# pse84_a0 register map
Vendor: Infineon Technologies; Series: PSE84_A0; File version: 1.0
CPU: CM33 r0p1, little endian, MPU, FPU, VTOR, 3 interrupt priority bits
Registers are 32-bit, read-write, reset 0x0 unless marked. A register's access mark holds for its fields unless they carry their own. Offsets are from the block's base; [hi:lo] are bit positions; lines under a group give offsets from that group; {n}, {i} and the like mark numbered series; 'fields as' and 'values as' point back to an identical list; <NAME> marks a mode.

## SRSS (part 1 of 2) — SRSS Core Registers
Base 0x42400000
{0x100+4i} CLK_DSI_SELECT[{i}] (i=0..15) — Clock DSI Select Register
  [4:0] DSI_MUX — Selects a DSI source or low frequency clock for use in a clock path. The output of this mux can be selected for clock PATH<i> using CLK_SELECT_PATH register. Using the output of this mux as HFCLK source will result in undefined behavior. It can be used to clocks to DSI or as reference inputs for the FLL/PLL, subject to the frequency limits of those circuits. This mux is not glitch free, so do not change the selection while it is an actively selected clock.
    {v}=DSI_OUT{v} (DSI{v} - dsi_out[{v}]) (v=0..15); 16=ILO (ILO - Internal Low-speed Oscillator #0); 17=WCO (WCO - Watch-Crystal Oscillator); 18=ALTLF (ALTLF - Alternate Low-Frequency Clock); 19=PILO (PILO - Precision Internal Low-speed Oscillator)
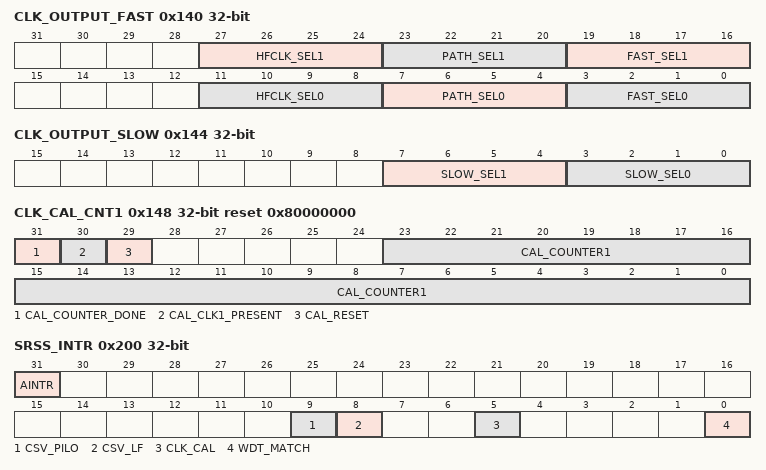
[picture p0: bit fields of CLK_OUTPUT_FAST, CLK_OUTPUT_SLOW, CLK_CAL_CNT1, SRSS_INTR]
0x140 CLK_OUTPUT_FAST — Fast Clock Output Select Register
  [27:24] HFCLK_SEL1 — Selects a HFCLK tree for use in fast clock output #1 logic
  [23:20] PATH_SEL1 — Selects a clock path to use in fast clock output #1 logic.
  [19:16] FAST_SEL1 — Select signal for fast clock output #1
    0=NC (Disabled - output is 0. For power savings, clocks are blocked before entering any muxes, including PATH_SEL1 and HFCLK_SEL1.); 1=HFSRC_0 (IHO - Internal High-speed Oscillator); 2=HFSRC_1 (EXTCLK - External Clock Pin); 3=HFSRC_2 (ECO - External-Crystal Oscillator (Product Specific)); 4=HFSRC_3 (IMO - Internal R/C Oscillator (Product Specific)); 5=HFSRC_4 (ALTHF0 - Alternate High-Frequency clock input (product-specific clock)); 6=HFSRC_5 (ALTHF1 - Alternate High-Frequency clock input (product-specific clock)); 7=HFSRC_6 (N/A); 8=TIMERCLK (Timer clock. It is grouped with the fast clocks because it may be a gated version of a fast clock, and therefore may have a short high pulse.); 9=PATH_SEL1 (Selects the clock path chosen by PATH_SEL1 field); 10=HFCLK_SEL1 (Selects the output of the HFCLK_SEL1 mux); 11=SLOW_SEL1 (Selects the output of CLK_OUTPUT_SLOW.SLOW_SEL1); 12=PWR (clk_pwr: used for PPU and related components)
  [11:8] HFCLK_SEL0 — Selects a HFCLK tree for use in fast clock output #0
  [7:4] PATH_SEL0 — Selects a clock path to use in fast clock output #0 logic.
  [3:0] FAST_SEL0 — Select signal for fast clock output #0
    0=NC (Disabled - output is 0. For power savings, clocks are blocked before entering any muxes, including PATH_SEL0 and HFCLK_SEL0.); 1=HFSRC_0 (IHO - Internal High-speed Oscillator); 2=HFSRC_1 (EXTCLK - External Clock Pin); 3=HFSRC_2 (ECO - External-Crystal Oscillator (Product Specific)); 4=HFSRC_3 (IMO - Internal R/C Oscillator (Product Specific)); 5=HFSRC_4 (ALTHF0 - Alternate High-Frequency clock input (product-specific clock)); 6=HFSRC_5 (ALTHF1 - Alternate High-Frequency clock input (product-specific clock)); 7=HFSRC_6 (N/A); 8=TIMERCLK (Timer clock. It is grouped with the fast clocks because it may be a gated version of a fast clock, and therefore may have a short high pulse.); 9=PATH_SEL0 (Selects the clock path chosen by PATH_SEL0 field); 10=HFCLK_SEL0 (Selects the output of the HFCLK_SEL0 mux); 11=SLOW_SEL0 (Selects the output of CLK_OUTPUT_SLOW.SLOW_SEL0); 12=PWR (clk_pwr: used for PPU and related components)
0x144 CLK_OUTPUT_SLOW — Slow Clock Output Select Register
  [7:4] SLOW_SEL1 — Select signal for slow clock output #1
    0=NC (Disabled - output is 0. For power savings, clocks are blocked before entering any muxes.); 1=ILO (Internal Low Speed Oscillator (ILO)); 2=WCO (Watch-Crystal Oscillator (WCO)); 3=CLK_RTC (Root of the RTC clock tree); 4=ALTLF (Alternate low-frequency clock input to SRSS (ALTLF)); 5=LFCLK (Root of the low-speed clock tree (LFCLK)); 6=IMO (Internal Main Oscillator (IMO). This is grouped with the slow clocks so it can be observed during DEEPSLEEP entry/exit.); 7=SLPCTRL (Sleep Controller clock (SLPCTRL). This is grouped with the slow clocks so it can be observed during DEEPSLEEP entry/exit.); 8=PILO (Precision Internal Low Speed Oscillator (PILO)); 9=ECO_PRESCALER (ECO Prescaler (ECO_PRESCALER)); 10=MF (Medium Frequency clock tree (MF)); 11=RSVD1 (N/A); 12=RSVD2 (N/A); 13=RSVD3 (N/A)
  [3:0] SLOW_SEL0 — Select signal for slow clock output #0
    values as SLOW_SEL1
0x148 CLK_CAL_CNT1 reset 0x80000000 — Clock Calibration Counter 1
  [31] CAL_COUNTER_DONE ro — Status bit indicating that the internal counter #1 is finished counting and CLK_CAL_CNT2.COUNTER stopped counting up
  [30] CAL_CLK1_PRESENT ro — Status bit indicating that a posedge was detected by counter #1 (does not apply when CLK_CAL_TEST.CAL_WINDOW_SEL = 1). If this bit never asserts, there is no clock on counter #1 and CAL_COUNTER_DONE will stay low indefinitely. This can be recovered with CAL_RESET.
  [29] CAL_RESET — Reset clock calibration logic for window mode. This can be used to recover from unexpected conditions, such as no clock present on counter #1. When entering window mode, set this bit, then set CLK_CAL_TEST.CAL_WINDOW_SEL=1, then clear this bit. It takes 3 clock cycles for this reset to propagate. A new calibration cannot start during this time.
  [23:0] CAL_COUNTER1 — Down-counter clocked on fast clock output #0 (see CLK_OUTPUT_FAST). This register always reads as zero. Counting starts internally when this register is written with a nonzero value. CAL_COUNTER_DONE goes immediately low to indicate that the counter has started and will be asserted when the counters are done. Do not write this field unless CAL_COUNTER_DONE==1. Both clocks must be running or the measurement will not complete, and this case can be recovered using CAL_RESET.
0x14C CLK_CAL_CNT2 ro — Clock Calibration Counter 2
  [23:0] CAL_COUNTER2 — Up-counter clocked on fast clock output #1 (see CLK_OUTPUT_FAST). When CLK_CAL_CNT1.CAL_COUNTER_DONE==1, the counter is stopped and can be read by SW. Do not read this value unless CAL_COUNTER_DONE==1. The expected final value is related to the ratio of clock frequencies used for the two counters and the value loaded into counter 1: CLK_CAL_CNT2.COUNTER=(F_cnt2/F_cnt1)*(CLK_CAL_CNT1.COUNTER)
0x200 SRSS_INTR — SRSS Interrupt Register
  [31] AINTR ro — See additional interrupts in SRSS_AINTR.
  [9] CSV_PILO — CSV_PILO Interrupt Request. This bit is set when PILO clock is below or above the expected limit
  [8] CSV_LF — CSV_LF Interrupt Request. This bit is set when LFCLK is below or above the expected limit
  [5] CLK_CAL — Clock calibration counter is done. This field is reset during DEEPSLEEP mode.
  [0] WDT_MATCH — WDT Interrupt Request. This bit is set each time WDT_COUNTR==WDT_MATCH. W1C also feeds the watch dog. Missing 2 interrupts in a row will generate a reset. Due to internal synchronization, it takes 2 SYSCLK cycles to update after a W1C.
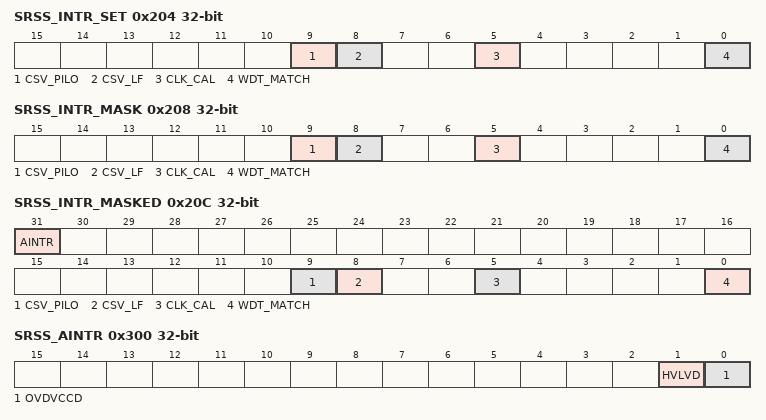
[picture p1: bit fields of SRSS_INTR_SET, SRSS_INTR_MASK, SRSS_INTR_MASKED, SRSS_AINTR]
0x204 SRSS_INTR_SET — SRSS Interrupt Set Register
  [9] CSV_PILO — Set interrupt for CSV_PILO
  [8] CSV_LF — Set interrupt for CSV_LF
  [5] CLK_CAL — Set interrupt for clock calibration counter done. This field is reset during DEEPSLEEP mode.
  [0] WDT_MATCH — Set interrupt for low voltage detector WDT_MATCH
0x208 SRSS_INTR_MASK — SRSS Interrupt Mask Register
  [9] CSV_PILO — Mask for interrupt for CSV_PILO
  [8] CSV_LF — Mask for interrupt for CSV_LF
  [5] CLK_CAL — Mask for clock calibration done
  [0] WDT_MATCH — Mask for watchdog timer. Clearing this bit will not forward the interrupt to the CPU. It will not, however, disable the WDT reset generation on 2 missed interrupts. When WDT resets the chip, it also internally pends an interrupt that survives the reset. To prevent unintended ISR execution, clear SRSS_INTR.WDT_MATCH before setting this bit.
0x20C SRSS_INTR_MASKED ro — SRSS Interrupt Masked Register
  [31] AINTR — See additional MASKED bits in SRSS_AINTR_MASKED.ADDITIONAL
  [9] CSV_PILO — Logical and of corresponding request and mask bits.
  [8] CSV_LF — Logical and of corresponding request and mask bits.
  [5] CLK_CAL — Logical and of corresponding request and mask bits.
  [0] WDT_MATCH — Logical and of corresponding request and mask bits.
0x300 SRSS_AINTR — SRSS Additional Interrupt Register
  [1] HVLVD — Interrupt for low voltage detector HVLVD
  [0] OVDVCCD — Interrupt for low voltage detector OVDVCCD. The OVD status should be cleared in PWR_SSV_STATUS before clearing this interrupt.
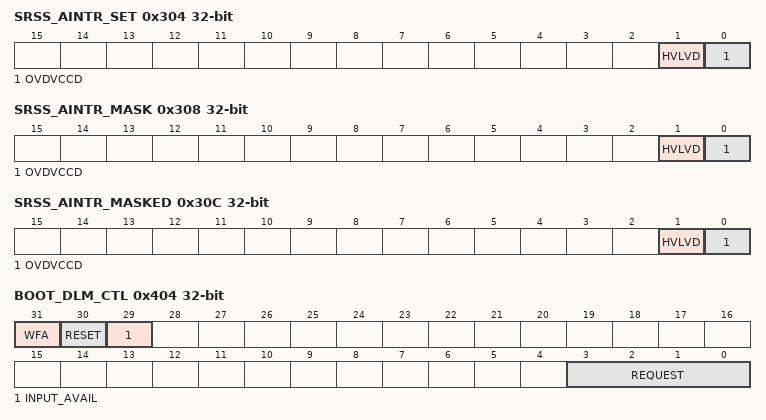
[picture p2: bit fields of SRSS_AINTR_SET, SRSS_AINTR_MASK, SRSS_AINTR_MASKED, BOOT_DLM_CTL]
0x304 SRSS_AINTR_SET — SRSS Additional Interrupt Set Register
  [1] HVLVD — Set interrupt for low voltage detector HVLVD. Note that the PWR_LVD_CTL.HVLVD_ACTION must be set to Interrupt for this SET functionality to work.
  [0] OVDVCCD — Set interrupt for low voltage detector OVDVCCD. Note that the PWR_OVD_CTL.OVDVCCD_ACTION must be set to Interrupt for this SET functionality to work.
0x308 SRSS_AINTR_MASK — SRSS Additional Interrupt Mask Register
  [1] HVLVD — Mask for low voltage detector HVLVD
  [0] OVDVCCD — Mask for low voltage detector OVDVCCD
0x30C SRSS_AINTR_MASKED ro — SRSS Additional Interrupt Masked Register
  [1] HVLVD — Logical and of corresponding request and mask bits.
  [0] OVDVCCD — Logical and of corresponding request and mask bits.
0x340 PWR_LVD_STATUS ro — High Voltage / Low Voltage Detector (HVLVD) Status Register
  [0] HVLVD_OK — HVLVD output. 0: below voltage threshold 1: above voltage threshold
0x404 BOOT_DLM_CTL — Debug Control Register
  [31] WFA — Wait for Action. Set by BootROM when it waits for application or debug certificate to be loaded into the RAM. The bit must be cleared to continue BootROM operation. It is used by the Sys-AP.
  [30] RESET — Request the device reset after RAM application complete input parameters processing. This bit is analyzed with APP_INPUT_AVAIL so to take effect write both. 0 - No action, the device waits for input parameters. 1 - Reset the device after input parameters processing complete.
  [29] INPUT_AVAIL — Notify RAM application that input parameters are valid for processing: 0 - the input parameters are not available. 1 - the input parameters are available (ready) for processing.
  [3:0] REQUEST
0x408 BOOT_DLM_CTL2 — Debug Control Register 2
  [31:0] APP_CTL — Address of application descriptor or debug certificate depends on DEBUG_TST_CTL.REQUEST. The application descriptor provides info about RAM application and its parameters layout in the staging area to BootROM and RAM application itself
0x40C BOOT_DLM_STATUS — Debug Status Register
  [31:0] DEBUG_STATUS — RAM application execution status or debug certificate validation status depends on DEBUG_TST_CTL.REQUEST. This status can be read by the debugger using Sys-AP or user application when RAM application completes with system reset. This field survives some resets, including a system reset
0x410 RES_SOFT_CTL — Soft Reset Trigger Register
  [0] TRIGGER_SOFT — Triggers a soft reset. The reset clears this bit.
0x418 BOOT_STATUS — Boot Execution Status Register
  [31:0] DEBUG_STATUS — Boot execution status. This status register can be used for communication between ROM_BOOT and User Application. This status can be read by the debugger using Sys-AP or User Application. This field survives some resets, including a system reset.
0x430 BOOT_ENTRY — Warm Boot Entry Address
  [31:0] WARM_BOOT_ENTRY — Warm boot entry point. This status register can be used for communication between 2 software application before/after DS-RAM or soft reset. This field survives low voltage resets, including a system reset.
{0x800+4i} PWR_HIB_DATA[{i}] (i=0..31) — Hibernate Data Register
  [31:0] HIB_DATA — Additional data that is retained through a HIBERNATE/WAKEUP sequence that can be used by firmware for any application-specific purpose. Note that waking up from HIBERNATE using XRES will reset this register.
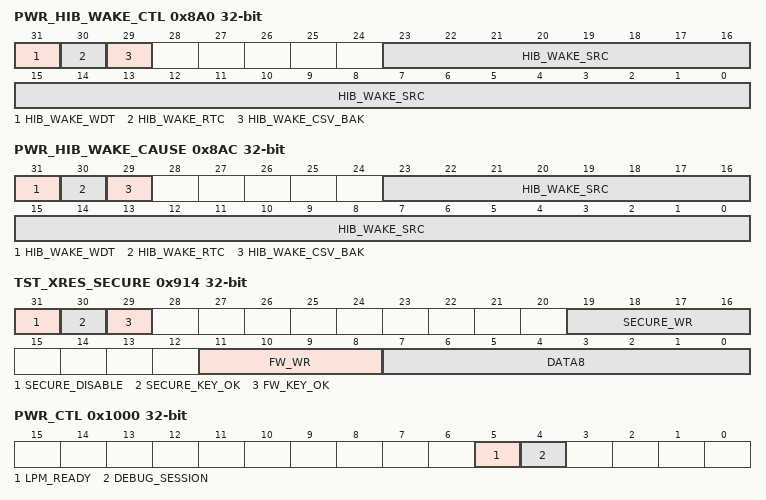
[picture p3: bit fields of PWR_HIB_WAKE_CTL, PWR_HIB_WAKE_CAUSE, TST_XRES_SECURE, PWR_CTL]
0x8A0 PWR_HIB_WAKE_CTL — Hibernate Wakeup Mask Register
  [31] HIB_WAKE_WDT — When set, HIBERNATE will wakeup for a pending WDT interrupt.
  [30] HIB_WAKE_RTC — When set, HIBERNATE will wakeup for a pending RTC interrupt.
  [29] HIB_WAKE_CSV_BAK — When set, HIBERNATE will wakeup for CSV_RTC detection.
  [23:0] HIB_WAKE_SRC — When set, HIBERNATE will wakeup for the assigned source The number and assignment of HIBERNATE wakeup sources are product-specific.
0x8A4 PWR_HIB_WAKE_CTL2 — Hibernate Wakeup Polarity Register
  [23:0] HIB_WAKE_SRC — Each bit selects the polarity for the corresponding HIBERNATE wakeup source. The number and assignment of wakeup sources are product-specific. 0: Wakes when unmasked input is 0. 1: Wakes when unmasked input is 1.
0x8AC PWR_HIB_WAKE_CAUSE — Hibernate Wakeup Cause Register
  [31] HIB_WAKE_WDT — Indicates WDT wakeup cause. The WDT interrupt must be cleared before this bit can be cleared.
  [30] HIB_WAKE_RTC — Indicates RTC wakeup cause. The RTC interrupt must be cleared before this bit can be cleared.
  [29] HIB_WAKE_CSV_BAK — Indicates CSV_RTC wakeup cause. The related fault must be handled before this bit can be cleared.
  [23:0] HIB_WAKE_SRC — Each bit indicates a HIBERNATE wakeup cause. The number and assigment of wakeup sources are product-specific. For each bit, writing a 1 clears the cause flag.
0x914 TST_XRES_SECURE — SECURE TEST and FIRMWARE TEST Key control register
  [31] SECURE_DISABLE — Disables the SECURE TEST key entry capability until next reset. Must not be set in the same write when any of the above *_WR bits are set or toggling.
  [30] SECURE_KEY_OK ro — Indicates that the 32-bit SECURE TEST key is observing the correct key. Secure key is not reset, but it will establish low after a deep power cycle that causes it to lose its written state.
  [29] FW_KEY_OK ro — Indicates that the 32-bit FIRMWARE TEST key is observing the correct key. Firmware key is reset by (A)XRES and STRUCT_XRES.
  [19:16] SECURE_WR — Latch enables for each of the 4 bytes in the 32-bit SECURE TEST key. Must be toggled high and then low while keeping DATA8 to the correct value.
  [11:8] FW_WR — Latch enables for each of the 4 bytes in the 32-bit FIRMWARE TEST key. Must be toggled high and then low while keeping DATA8 to the correct value.
  [7:0] DATA8 — Data byte to be set into either SECURE TEST or FIRMWARE TEST key. Must not be changed in the same write that is toggling any of the *_WR bits below,
0x1000 PWR_CTL ro — Power Mode Control
  [5] LPM_READY — Indicates whether certain low power functions are ready. The low current circuits take longer to startup after XRES, HIBERNATE wakeup, or supply supervision reset wakeup than the normal mode circuits. HIBERNATE mode may be entered regardless of this bit. 0: If a low power circuit operation is requested, it will stay in its normal operating mode until it is ready. If DEEPSLEEP is requested by all processors WFI/WFE, the device will instead enter SLEEP. When low power circuits are ready, device will automatically enter the originally requested mode. 1: Normal operation. DEEPSLEEP and low power circuits operate as requested in other registers.
  [4] DEBUG_SESSION — Indicates whether a debug session is active (CDBGPWRUPREQ signal is 1)
    0=NO_SESSION (No debug session active); 1=SESSION_ACTIVE (Debug session is active. Power modes behave differently to keep the debug session active, and current consumption may be higher than datasheet specification.)
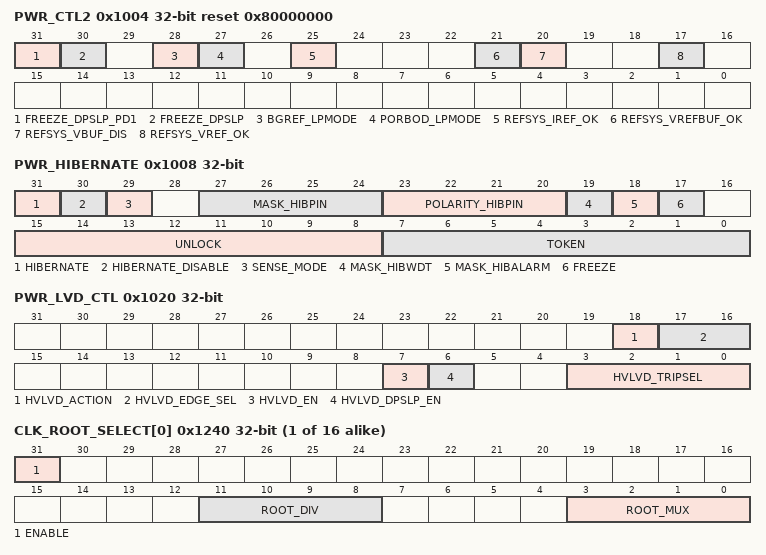
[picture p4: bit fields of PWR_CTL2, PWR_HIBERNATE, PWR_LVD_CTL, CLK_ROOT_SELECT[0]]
0x1004 PWR_CTL2 reset 0x80000000 — Power Mode Control 2
  [31] FREEZE_DPSLP_PD1 — Controls whether mode and state of GPIOs and SIOs in Power Domain 1 are frozen. This is intended to be used as part of the DEEPSLEEP-RAM and DEEPSLEEP-OFF entry and exit sequences. It is set by HW when PD1 enters DEEPSLEEP-RAM and DEEPSLEEP-OFF modes. Writing a 1 clears freeze and GPIOs and SIOs resume normal operation.
  [30] FREEZE_DPSLP — Controls whether mode and state of GPIOs and SIOs in Power Domain 0 are frozen. This is intended to be used as part of the DEEPSLEEP-RAM and DEEPSLEEP-OFF entry and exit sequences. It is set by HW when PD0 enters DEEPSLEEP-RAM and DEEPSLEEP-OFF modes. Writing a 1 clears freeze and GPIOs and SIOs resume normal operation.
  [28] BGREF_LPMODE — Control the circuit-level power mode of the Bandgap Reference circuits for DEEPSLEEP. This selects a second set of bandgap voltage and current generation circuits that are optimized for low current consumption. This register is only reset by XRES, HIBERNATE wakeup, or supply supervision reset. The setting is ignored during ACTIVE mode. 0: Bandgap Reference uses the normal settings. 1: Bandgap Reference uses the low power sample and hold circuits.
  [27] PORBOD_LPMODE — Control the power mode of the POR/BOD circuits in DEEPSLEEP modes. The value in this register is ignored and normal mode is used until LPM_READY==1. This register is only reset by XRES, HIBERNATE wakeup, or supply supervision reset. 0: POR/BOD circuits operate in normal mode during DEEPSLEEP. 1: POR/BOD circuits operate in low power mode during DEEPSLEEP. Response time is reduced to save current.
  [25] REFSYS_IREF_OK ro — Indicates that the current reference is ready. Due to synchronization delays, it may take two IHO clock cycles for hardware to clear this bit after asserting REFI_DIS=1.
  [21] REFSYS_VREFBUF_OK ro — Indicates that the voltage reference buffer is ready. Due to synchronization delays, it may take two IHO clock cycles for hardware to clear this bit after asserting REFVBUF_DIS=1.
  [20] REFSYS_VBUF_DIS — Disable the voltage reference buffer. Firmware should only disable the buffer when there is no connected circuit that is using it. SRSS circuits that require it are the DPLL and ECO. A particular product may have circuits outside the SRSS that use the buffer. This register is only reset by XRES, HIBERNATE wakeup, or supply supervision reset.
  [17] REFSYS_VREF_OK ro — Indicates that the normal mode of the voltage reference is ready.
0x1008 PWR_HIBERNATE — HIBERNATE Mode Register
  [31] HIBERNATE — Firmware sets this bit to enter HIBERNATE mode. The system will enter HIBERNATE mode immediately after writing to this bit and will wakeup only in response to XRES or WAKEUP. Both UNLOCK and FREEZE must have been set correctly in a previous write operations. Otherwise, it will not enter HIBERNATE. External supplies must have been stable for 250us before entering HIBERNATE mode.
  [30] HIBERNATE_DISABLE — Hibernate disable bit. 0: Normal operation, HIBERNATE works as described 1: Further writes to this register are ignored Note: This bit is a write-once bit until the next reset. Avoid changing any other bits in this register while disabling HIBERNATE mode. Also, it is recommended to clear the UNLOCK code, if it was previously written..
  [29] SENSE_MODE — Power mode when wakeups are sensitive. The default of this field is 0 for software compatibility with other products. It is recommended to set this field to 1 for new/updated software. 0: Wakeups are sensitive only during HIBERNATE mode. A wakeup pulse that comes just before HIBERNATE entry may be missed. Backward compatible. 1: Wakeups are sensitive in HIBERNATE and higher modes. Before entering HIBERNATE, software must clear all unmasked, pending wakeups in PWR_HIB_WAKE_CAUSE register. An unmasked, pending wakeup causes HIBERNATE wakeup, even if it was pending from before HIBERNATE entry. This prevents missed wakeups.
  [27:24] MASK_HIBPIN
  [23:20] POLARITY_HIBPIN
  [19] MASK_HIBWDT
  [18] MASK_HIBALARM
  [17] FREEZE — Controls whether mode and state of GPIOs and SIOs in the system are frozen. This is intended to be used as part of the HIBERNATE entry and exit sequences. When entering HIBERNATE mode, the first write instructs DEEPSLEEP peripherals that they cannot ignore the upcoming freeze command. This occurs even in the illegal condition where UNLOCK is not set. If UNLOCK and HIBERNATE are properly set, the IOs actually freeze on the second write. Supply supervision is disabled during HIBERNATE mode. HIBERNATE peripherals ignore resets (excluding XRES) while FREEZE==1.
  [15:8] UNLOCK — This byte must be set to 0x3A for FREEZE or HIBERNATE fields to operate. Any other value in this register will cause FREEZE/HIBERNATE to have no effect, except as noted in the FREEZE description.
  [7:0] TOKEN — Contains a 8-bit token that is retained through a HIBERNATE/WAKEUP sequence that can be used by firmware to differentiate WAKEUP from a general RESET event. Note that waking up from HIBERNATE using XRES,or a WDT reset will reset this register.
0x1020 PWR_LVD_CTL — High Voltage / Low Voltage Detector (HVLVD) Configuration Register
  [18] HVLVD_ACTION — Action taken when the threshold is crossed in the programmed directions(s)
    0=INTERRUPT (Generate an interrupt); 1=FAULT (Generate a fault)
  [17:16] HVLVD_EDGE_SEL — Sets which edge(s) will trigger an action when the threshold is crossed.
    0=DISABLE (Disabled); 1=RISING (Rising edge); 2=FALLING (Falling edge); 3=BOTH (Both rising and falling edges)
  [7] HVLVD_EN — Enable HVLVD voltage monitor. Do not change other HVLVD settings when enabled.
  [6] HVLVD_DPSLP_EN — 1 = Enable HVLVD voltage monitor during Deepsleep if HVLVD_EN=1, but the response will be slowed to save power. 0 = HVLVD does not function during DEEPSLEEP, but it automatically returns to its configured setting after DEEPSLEEP wakeup.
  [3:0] HVLVD_TRIPSEL — Threshold selection for HVLVD. Disable the detector (HVLVD_EN=0) before changing the threshold. 0: rise=2.78V (nom), fall=2.75V (nom) 1: rise=2.88V (nom), fall=2.85V (nom) 2: rise=2.98V (nom), fall=2.95V (nom) 3: rise=3.08V (nom), fall=3.05V (nom) 4: rise=3.18V (nom), fall=3.15V (nom)
{0x1200+4i} CLK_PATH_SELECT[{i}] (i=0..15) — Clock Path Select Register
  [2:0] PATH_MUX — Selects a source for clock PATH<i>. Note that not all products support all clock sources. Selecting a clock source that is not supported will result in undefined behavior. It takes four cycles of the originally selected clock to switch away from it. Do not disable the original clock during this time.
    0=HFSRC_0 (IHO - Internal High-speed Oscillator); 1=HFSRC_1 (EXTCLK - External Clock Pin); 2=HFSRC_2 (ECO - External-Crystal Oscillator (Product Specific)); 3=HFSRC_3 (IMO - Internal R/C Oscillator (Product Specific)); 4=HFSRC_4 (ALTHF0 - Alternate High-Frequency clock input (product-specific clock)); 5=HFSRC_5 (ALTHF1 - Alternate High-Frequency clock input (product-specific clock)); 6=HFSRC_6 (N/A); 7=HFSRC_7 (DSI_MUX - Output of DSI mux for this path. Using a DSI source directly as root of HFCLK will result in undefined behavior.)
{0x1240+4i} CLK_ROOT_SELECT[{i}] (i=0..15) — Clock Root Select Register
  [31] ENABLE — Enable for this clock root. All clock roots default to disabled (ENABLE==0) except HFCLK0, which cannot be disabled.
  [11:8] ROOT_DIV — Selects predivider value for this clock root and DSI input. This divider is after DIRECT_MUX. For products with DSI, the output of this mux is routed to DSI for use as a signal. For products with clock supervision, the output of this mux is the monitored clock for CSV_HF<k>.
    0=NO_DIV (Transparent mode, feed through selected clock source w/o dividing.); {v}=DIV_BY_{v+1} (Divide selected clock source by {v+1}) (v=1..15)
  [3:0] ROOT_MUX — Selects a clock path for HFCLK<k> and SRSS DSI input <k>. The output of this mux goes to the direct mux (see CLK_DIRECT_SELECT). Use CLK_SELECT_PATH[i] to configure the desired path. The number of clock paths is product-specific, and selecting an unimplemented path is not supported. Some paths may have PLL available (product-specific), and the control and bypass mux selections of these are in other registers. Configure a PLL using the related CLK_PLL_CONFIG[k] register. Note that not all products support all clock sources. Selecting a clock source that is not supported will result in undefined behavior. It takes four cycles of the originally selected clock to switch away from it. Do not disable the original clock during this time. When switching to a different clock source, ensure that the ROOT_DIV is set to an appropriate value BEFORE changing the ROOT_MUX to avoid a temporary over/under-shoot in clock frequency that will occur if both fields are changed at the same time.
    {v}=PATH{v} (Select PATH{v}) (v=0..15)
{0x1280+4i} CLK_DIRECT_SELECT[{i}] (i=0..15) — Clock Root Direct Select Register
  [8] DIRECT_MUX — Direct selection mux that allows IHO to bypass most of the clock mux structure. For products with multiple regulators, this mux can be used to reduce current without requiring significant reconfiguration of the clocking network. The default value of HFCLK<0>==ROOT_MUX, and the default value for other clock trees is product-specific.
    0=IHO (Select IHO); 1=ROOT_MUX (Select ROOT_MUX selection)
0x1300 CLK_SELECT — Clock selection register
  [2:0] LFCLK_SEL — Select source for LFCLK. Note that not all products support all clock sources. Selecting a clock source that is not supported will result in undefined behavior. Writes to this field are ignored unless the WDT is unlocked using WDT_LOCK register. It takes four cycles of the originally selected clock to switch away from it. Do not disable the original clock during this time.
    0=PILO (PILO - Precision ILO, if present.); 1=WCO (WCO - Watch-Crystal Oscillator. Requires properly configured (including external watch crystal, if used), if present); 2=ALTLF (ALTLF - Alternate Low-Frequency Clock. Capability is product-specific); 3=ECO_PRESCALER (ECO_PRESCALER - External-Crystal Oscillator after prescaling, if present. Does not work in DEEPSLEEP or HIBERNATE modes. Intended for applications that operate in ACTIVE/SLEEP modes only. This option is only valid when ECO is present in the product. User must ensure that the CLK_ECO_PRESCALE is configured to generate a 32KHz clock when using this option.); 4=ILO (ILO - Internal Low-speed Oscillator, if present)
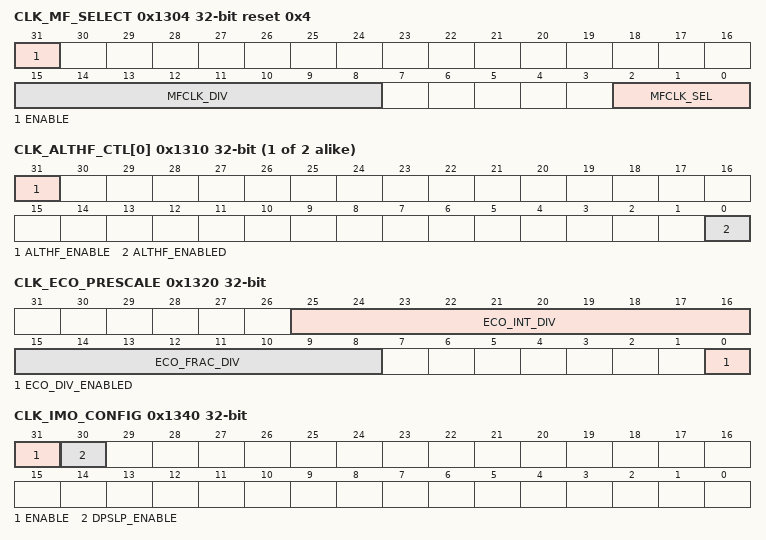
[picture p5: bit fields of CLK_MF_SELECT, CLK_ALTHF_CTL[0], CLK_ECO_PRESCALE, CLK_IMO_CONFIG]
0x1304 CLK_MF_SELECT reset 0x4 — Medium Frequency Clock Select Register
  [31] ENABLE — Enable for MFCLK (clk_mf). When disabling clk_mf, do not disable the source until after 5 clk_mf periods. clk_mf continues to operate in DEEPSLEEP for compatible sources. Firmware must disable clk_mf before entering DEEPSLEEP if the source is not compatible with DEEPSLEEP mode.
  [15:8] MFCLK_DIV — Divide selected clock source by (1+MFCLK_DIV). The output of this divider is MFCLK (clk_mf). Allows for integer divisions in the range [1, 256]. Do not change this setting while ENABLE==1.
  [2:0] MFCLK_SEL — Select source for MFCLK (clk_mf). Note that not all products support all clock sources. Selecting a clock source that is not supported results in undefined behavior.
    0=IMO (Internal Main Oscillator (IMO). DEEPSLEEP compatibility is product-specific. See CLK_IMO_CONFIG for capability of this product.); 1=ILO (ILO - Internal Low-speed Oscillator.); 2=WCO (WCO - Watch-Crystal Oscillator, if present.); 3=ALTLF (ALTLF - Alternate Low-Frequency Clock. Capability is product-specific); 4=PILO (PILO - Precision ILO, if present.); 5=ECO_PRESCALER (ECO_PRESCALER - External-Crystal Oscillator, if present, after prescaling in CLK_ECO_PRESCALE. Intended for applications that operate in ACTIVE/SLEEP modes only. Does not work in DEEPSLEEP mode.); 6=IHO (IHO clock. MFCLK_DIV should be >0 to achieve MF frequency. DEEPSLEEP compatibility is product-specific. See CLK_IHO_CONFIG for capability of this product.); 7=RSVD2 (N/A)
{0x1310+4i} CLK_ALTHF_CTL[{i}] (i=0..1) — Alternate High Frequency Clock Control Register
  [31] ALTHF_ENABLE — Enable for ALTHF clock when used by SRSS. There may be independent control of ALTHF by another subsystem, and this bit prevents ALTHF from being disabled when SRSS needs it. SRSS automatically removes its enable request during DEEPSLEEP and lower modes.
  [0] ALTHF_ENABLED ro — Indicates that ALTHF is actually enabled. The delay between a transition on ALTHF_ENABLE and ALTHF_ENABLED is product specific.
0x1320 CLK_ECO_PRESCALE — ECO Prescaler Configuration Register
  [25:16] ECO_INT_DIV — 10-bit integer value allows for ECO frequencies up to 33.55MHz. Subtract one from the desired divide value when writing this field. For example, to divide by 1, write ECO_INT_DIV=0. Do not change this setting when ECO Prescaler is enabled.
  [15:8] ECO_FRAC_DIV — 8-bit fractional value, sufficient to get prescaler output within the +/-65ppm calibration range. Do not change this setting when ECO Prescaler is enabled.
  [0] ECO_DIV_ENABLED ro — ECO prescaler enabled. HW sets this field to '1' as a result of an CLK_ECO_CONFIG.ECO_DIV_ENABLE command. HW sets this field to '0' as a result on a CLK_ECO_CONFIG.ECO_DIV_DISABLE command. ECO prescaler is incompatible with DEEPSLEEP modes, and firmware must disable it before entering DEEPSLEEP.
0x1340 CLK_IMO_CONFIG — IMO Configuration
  [31] ENABLE — Master enable for IMO oscillator. Hardware will automatically disable the IMO during HIBERNATE and XRES. It will automatically disable during DEEPSLEEP if DPSLP_ENABLE==0.
  [30] DPSLP_ENABLE — Enable for IMO during DEEPSLEEP. This bit configures IMO behavior during DEEPSLEEP: 0: IMO is automatically disabled during DEEPSLEEP and enables upon wakeup; 1: IMO is kept enabled throughout DEEPSLEEP
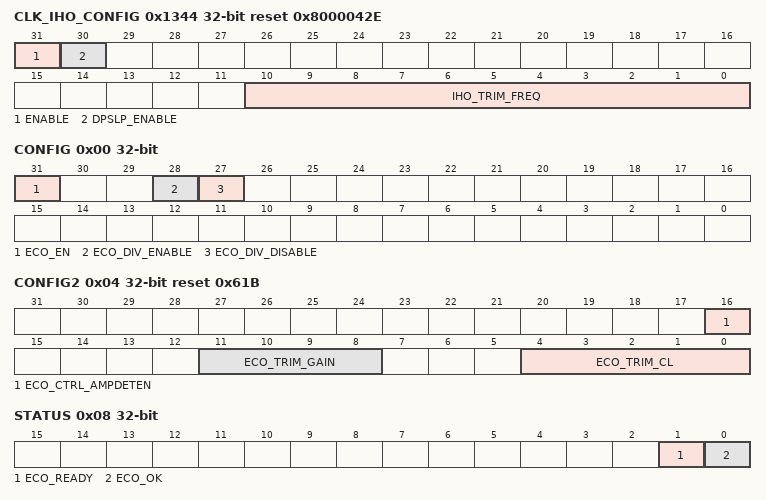
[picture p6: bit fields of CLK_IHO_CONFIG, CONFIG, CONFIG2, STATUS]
0x1344 CLK_IHO_CONFIG reset 0x8000042E — IHO Configuration Register
  [31] ENABLE — Master enable for IHO oscillator. This bit must be high at all times for all functions to work properly. Hardware will automatically disable the IHO during HIBERNATE and XRES. It will automatically disable during DEEPSLEEP if DPSLP_ENABLE==0.
  [30] DPSLP_ENABLE — Enable for IHO during DEEPSLEEP. This bit configures IHO behavior during DEEPSLEEP: 0: IHO is automatically disabled during DEEPSLEEP and enables upon wakeup; 1: IHO is kept enabled throughout DEEPSLEEP
  [10:0] IHO_TRIM_FREQ — IHO frequency trim
0x1360 CLK_ECO group — ECO Configuration
  0x00 CONFIG — ECO Configuration Register
    [31] ECO_EN — Master enable for ECO oscillator. Configure the settings in CLK_ECO_CONFIG2 to work with the selected crystal, before enabling ECO.
    [28] ECO_DIV_ENABLE — ECO prescaler enable command (mutually exclusive with ECO_DIV_DISABLE). ECO Prescaler only works in ACTIVE and SLEEP modes. SW sets this field to '1' to enable the divider and HW sets this field to '0' to indicate that divider enabling has completed. When the divider is enabled, its integer and fractional counters are initialized to '0'. If a divider is to be re-enabled using different integer and fractional divider values, the SW should follow these steps: 0: Disable the divider using the ECO_DIV_DISABLE field. 1: Configure CLK_ECO_PRESCALE registers. 2: Enable the divider using the ECO_DIV_ENABLE field. HW sets the ECO_DIV_ENABLE field to '0' when the enabling is performed and HW set CLK_ECO_PRESCALER.ENABLED to '1' when the enabling is performed.
    [27] ECO_DIV_DISABLE — ECO prescaler disable command (mutually exclusive with ECO_DIV_ENABLE). SW sets this field to '1' and HW sets this field to '0'. HW sets ECO_DIV_DISABLE field to '0' immediately and HW sets CLK_ECO_PRESCALE.ECO_DIV_EN field to '0' immediately.
  0x04 CONFIG2 reset 0x61B — ECO Configuration Register 2
    [16] ECO_CTRL_AMPDETEN — Amplifer detect enable
    [11:8] ECO_TRIM_GAIN — Gain trim
    [4:0] ECO_TRIM_CL — Crystal load cap configuration trim
  0x08 STATUS ro — ECO Status Register
    [1] ECO_READY — Indicates the ECO internal oscillator circuit power has had enough time to fully stabilize and the CLK_EN can be set. The ECO_OK bit should be used to determine that the ECO is ready for use.
    [0] ECO_OK — Indicates the ECO internal oscillator circuit has sufficient amplitude. It may not meet the PPM accuracy or duty cycle spec.
0x1370 CLK_PILO_CONFIG reset 0x80000000 — Precision ILO Configuration Register
  [31] PILO_EN — Enable PILO. If the PILO is the selected source for WDT, writes to this field are ignored unless the WDT is unlocked using WDT_LOCK register. To save power FW must disable PILO upon entry to Hibernate if it is not used as a Hibernate clock source. PILO will continue to run in XRES if enabled.
0x1374 CLK_PILO_STATUS ro — Precision ILO Status Register
  [0] PILO_OK — Indicates the PILO is running.
0x1380 CLK_ILO_CONFIG reset 0x80000000 — ILO Configuration
  [31] ENABLE — Enable ILO. If the ILO is the selected source for WDT, writes to this field are ignored unless the WDT is unlocked using WDT_LOCK register. To save power, FW must disable ILO upon entry to Hibernate if it is not used as a Hibernate clock source. ILO will continue to run in XRES if enabled.
0x1384 CLK_TRIM_ILO_CTL reset 0x2C — ILO Trim Register
  [5:0] ILO_FTRIM — IL0 frequency trims. LSB step size is 1.5 percent (typical) of the frequency. If the ILO is the selected source for WDT, writes to this field are ignored unless the WDT is unlocked using WDT_LOCK register.
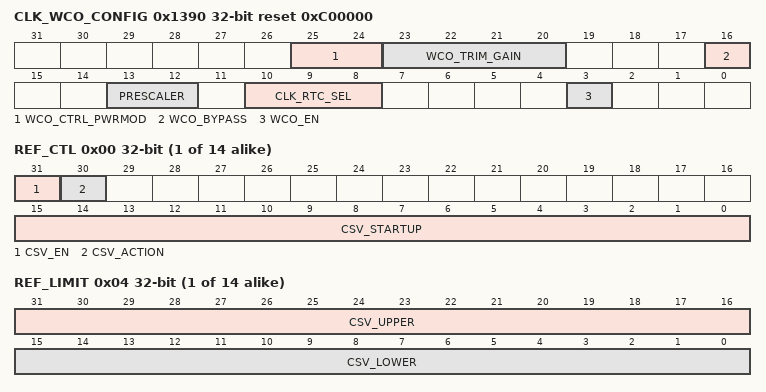
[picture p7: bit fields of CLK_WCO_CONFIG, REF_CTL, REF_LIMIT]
0x1390 CLK_WCO_CONFIG reset 0xC00000 — WCO Configuration Register
  [25:24] WCO_CTRL_PWRMOD
  [23:20] WCO_TRIM_GAIN — main amplifier gain control. Please use S22SRSSA_WCO_CALCULATOR to obtain appropriate value for the attached crystal. Writes to this field are ignored unless the WDT is unlocked using WDT_LOCK register
  [16] WCO_BYPASS — Configures the WCO for different board-level connections to the WCO pins. For example, this can be used to connect an external watch crystal oscillator instead of a watch crystal. In all cases, the two related GPIO pins (WCO input and output pins) must be configured as analog connections using GPIO registers, and they must be hooked at the board level as described below. Configure this field before enabling the WCO, and do not change this setting when WCO_EN=1. Also if the BAK (RTC) is the selected source for WDT, Writes to this field are ignored unless the WDT is unlocked using WDT_LOCK register. 0: Watch crystal. Connect a 32.768 kHz watch crystal between WCO input and output pins. 1: Clock signal, either a square wave or sine wave. See PRESCALER field for connection information.
  [13:12] PRESCALER
  [10:8] CLK_RTC_SEL — Clock select for RTC clock. If the BAK (RTC) is the selected source for WDT, Writes to this field are ignored unless the WDT is unlocked using WDT_LOCK register. Selecting a clock that is not running results in unpredictable behavior.
    0=WCO (Watch-crystal oscillator input, available in Active, DeepSleep and Hibernate.); 1=ALTBAK (This allows to use the LFCLK selection as an alternate backup domain clock. Note that LFCLK is only available in Active and DeepSleep power modes. Note that LFCLK clock glitches can propagate into the RTC logic when the clock is stopped. For this reason, if the WCO, PILO or ILO is intended as the clock source then choose it directly instead of routing through LFCLK.); 2=ILO (Internal Low frequency Oscillator, available in Active, DeepSleep, and Hibernate. With this option selected, ILO reset is suppressed in XRES/Hibernate modes.); 3=PILO (Precision internal low-speed oscillator, available in Active, DeepSleep, and Hibernate. With this option selected, PILO reset is suppressed in XRES/Hibernate modes.); 4=RSVD (N/A)
  [3] WCO_EN — Watch-crystal oscillator (WCO) enable. If there is an RTC write in progress and WCO is the clock source for clk_rtc when this bit is cleared, the WCO will be internally kept on until the write completes. After enabling the WCO software must wait until CLK_WCO_STATUS.WCO_OK=1 before configuring any component that depends on clk_lf/clk_rtc, like for example RTC or WDTs. If the BAK (RTC) is the selected source for WDT, writes to this field are ignored unless the WDT is unlocked using WDT_LOCK register.
0x1394 CLK_WCO_STATUS ro — WCO Status Register
  [2] WCO_OK — Indicates that output has transitioned.
0x1400 CSV_HF group — Clock Supervisor (CSV) registers for Root clocks
  {0x0+0x10*j} CSV[{j}] (j=0..13) group — Active domain Clock Supervisor (CSV) registers
    0x00 REF_CTL — Clock Supervision Reference Control
      [31] CSV_EN — Enables clock supervision, both frequency and loss. CSV in Active domain: Clock supervision is reset during DeepSleep and Hibernate modes. When enabled it begins operating automatically after a DeepSleep wakeup, but it must be reconfigured after Hibernate wakeup. CSV in DeepSleep domain: Clock supervision is reset during Hibernate mode. It must be reconfigured after Hibernate wakeup. A CSV error detection is reported to the Fault structure, or instead it can generate a power reset.
      [30] CSV_ACTION — Specifies the action taken when an anomaly is detected on the monitored clock. CSV in DeepSleep domain always do a Fault report (which also wakes up the system).
        0=FAULT (Generate a fault); 1=RESET (Cause a power reset. This should only be used for clk_hf0.)
      [15:0] CSV_STARTUP — Startup delay time -1 (in reference clock cycles), after enable or DeepSleep wakeup, from reference clock start to monitored clock start. At a minimum (both clocks running): STARTUP >= (PERIOD +3) * FREQ_RATIO - UPPER, with FREQ_RATIO = (Reference frequency / Monitored frequency) On top of that the actual clock startup delay and the margin for accuracy of both clocks must be added.
    0x04 REF_LIMIT — Clock Supervision Reference Limits
      [31:16] CSV_UPPER — Cycle time upper limit. Set the upper limit -1, in reference clock cycles, before (or same time) the next monitored clock event must happen. If a monitored clock event does not happen before this limit is reached, or does not happen at all (clock loss), a CSV error is detected.
      [15:0] CSV_LOWER — Cycle time lower limit. Set the lower limit -1, in reference clock cycles, before the next monitored clock event is allowed to happen. If a monitored clock event happens before this limit is reached a CSV error is detected. LOWER must be at least 1 less than UPPER. In case the clocks are asynchronous LOWER must be at least 3 less than UPPER.
    0x08 MON_CTL — Clock Supervision Monitor Control
      [15:0] CSV_PERIOD — Period time. Set the Period -1, in monitored clock cycles, before the next monitored clock event happens. PERIOD <= (UPPER+1) / FREQ_RATIO -1, with FREQ_RATIO = (Reference frequency / Monitored frequency) In case the clocks are asynchronous: PERIOD <= UPPER / FREQ_RATIO -1 Additionally margin must be added for accuracy of both clocks.
0x1500 CSV_REF_SEL reset 0x4 — Select CSV Reference clock for Active domain
  [2:0] REF_MUX — Selects a source for clock clk_ref_hf. Note that not all products support all clock sources. Selecting a clock source that is not supported will result in undefined behavior. It takes four cycles of the originally selected clock to switch away from it. Do not disable the original clock during this time.
    0=IMO (IMO - Internal R/C Oscillator (product specific)); 1=EXTCLK (EXTCLK - External Clock Pin); 2=ECO (ECO - External-Crystal Oscillator); 3=ALTHF0 (ALTHF0 - Alternate High-Frequency clock input (product-specific clock)); 4=IHO (IHO - Internal High-speed Oscillator); 5=ALTHF1 (ALTHF1 - Alternate High-Frequency clock input (product-specific clock))
0x1510 CSV_REF group — CSV registers for the CSV Reference clock
  0x00 CSV group — Active domain Clock Supervisor (CSV) registers for CSV Reference clock
    0x00 REF_CTL — Clock Supervision Reference Control
      fields as CSV_HF.CSV[0].REF_CTL
    0x04 REF_LIMIT — Clock Supervision Reference Limits
      fields as CSV_HF.CSV[0].REF_LIMIT
    0x08 MON_CTL — Clock Supervision Monitor Control
      fields as CSV_HF.CSV[0].MON_CTL
0x1520 CSV_LF_REF_SEL — Select CSV Reference clock for LF clock
  [1:0] LF_REF_MUX — Selects a source for clock clk_ref_lf. Note that not all products support all clock sources. Selecting a clock source that is not supported will result in undefined behavior. It takes four cycles of the originally selected clock to switch away from it. Do not disable the original clock during this time. Same clcok sources are also souce for clk_lf. Do not select the same clock.
    0=PILO (Precision internal low-speed oscillator, available in Active, DeepSleep, and Hibernate. (Product Specific)); 1=ILO (Internal Low frequency Oscillator, available in Active, DeepSleep, and Hibernate. (Product Specific)); 2=WCO (Watch-crystal oscillator input, available in Active, DeepSleep, and Hibernate. (Product Specific)); 3=TIMERCLK (Timer clock. Divided clock from IHO set to 1MHz. Available only during Active mode. If this clock is selected as reference, CSV will be disabled by hardware when entering lower power modes (DPSLP) and re-enabled back in Active.)
0x1530 CSV_LF group — CSV registers for LF clock
  0x00 CSV group — LF clock Clock Supervisor registers
    0x00 REF_CTL — Clock Supervision Reference Control
      [31] CSV_EN — Enables clock supervision, both frequency and loss. CSV in Active domain: Clock supervision is reset during DeepSleep and Hibernate modes. When enabled it begins operating automatically after a DeepSleep wakeup, but it must be reconfigured after Hibernate wakeup. CSV in DeepSleep domain: Clock supervision is reset during Hibernate mode. It must be reconfigured after Hibernate wakeup. CSV in Backup domain: Clock supervision operates during Hibernate mode, can be configured to wake from Hibernate, and continues operating during reboot. A CSV error detection is reported to the Fault structure.
      [7:0] CSV_STARTUP — Startup delay time -1 (in reference clock cycles), after enable, from reference clock start to monitored clock start. At a minimum (both clocks running): STARTUP >= (PERIOD +3) * FREQ_RATIO - UPPER, with FREQ_RATIO = (Reference frequency / Monitored frequency) On top of that the actual clock startup delay and the margin for accuracy of both clocks must be added.
    0x04 REF_LIMIT — Clock Supervision Reference Limits
      [23:16] CSV_UPPER — Cycle time upper limit. Set the upper limit -1, in reference clock cycles, before (or same time) the next monitored clock event must happen. If a monitored clock event does not happen before this limit is reached, or does not happen at all (clock loss), a CSV error is detected.
      [7:0] CSV_LOWER — Cycle time lower limit. Set the lower limit -1, in reference clock cycles, before the next monitored clock event is allowed to happen. If a monitored clock event happens before this limit is reached a CSV error is detected. LOWER must be at least 1 less than UPPER. In case the clocks are asynchronous LOWER must be at least 3 less than UPPER.
    0x08 MON_CTL — Clock Supervision Monitor Control
      [7:0] CSV_PERIOD — Period time. Set the Period -1, in monitored clock cycles, before the next monitored clock event happens. PERIOD <= (UPPER+1) / FREQ_RATIO -1, with FREQ_RATIO = (Reference frequency / Monitored frequency) In case the clocks are asynchronous: PERIOD <= UPPER / FREQ_RATIO -1 Additionally margin must be added for accuracy of both clocks.
